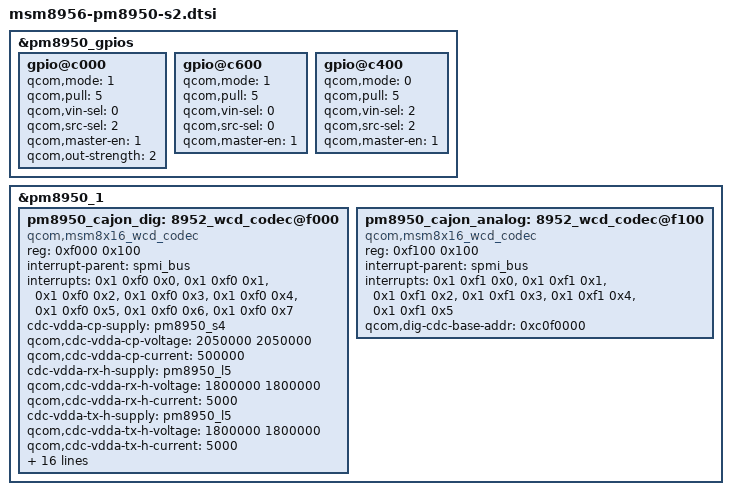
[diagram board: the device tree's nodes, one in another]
&pm8950_gpios {
	gpio@c000 {
		status = "ok";
		qcom,mode = <1>;
		qcom,pull = <5>;
		qcom,vin-sel = <0>;
		qcom,src-sel = <2>;
		qcom,master-en = <1>;
		qcom,out-strength = <2>;
	};
	gpio@c600 {
		status = "ok";
		qcom,mode = <1>;
		qcom,pull = <5>;
		qcom,vin-sel = <0>;
		qcom,src-sel = <0>;
		qcom,master-en = <1>;
	};
	gpio@c400 {
		qcom,mode = <0>;
		qcom,pull = <5>;
		qcom,vin-sel = <2>;
		qcom,src-sel = <2>;
		qcom,master-en = <1>;
		status = "okay";
	};
};


&pm8950_1 {
	pm8950_cajon_dig: 8952_wcd_codec@f000 {
		compatible = "qcom,msm8x16_wcd_codec";
		reg = <0xf000 0x100>;
		interrupt-parent = <&spmi_bus>;
		interrupts = <0x1 0xf0 0x0>,
			     <0x1 0xf0 0x1>,
			     <0x1 0xf0 0x2>,
			     <0x1 0xf0 0x3>,
			     <0x1 0xf0 0x4>,
			     <0x1 0xf0 0x5>,
			     <0x1 0xf0 0x6>,
			     <0x1 0xf0 0x7>;
		interrupt-names = "spk_cnp_int",
				  "spk_clip_int",
				  "spk_ocp_int",
				  "ins_rem_det1",
				  "but_rel_det",
				  "but_press_det",
				  "ins_rem_det",
				  "mbhc_int";

		cdc-vdda-cp-supply = <&pm8950_s4>;
		qcom,cdc-vdda-cp-voltage = <2050000 2050000>;
		qcom,cdc-vdda-cp-current = <500000>;
		
		cdc-vdda-rx-h-supply = <&pm8950_l5>;
		qcom,cdc-vdda-rx-h-voltage = <1800000 1800000>;
		qcom,cdc-vdda-rx-h-current = <5000>;

		cdc-vdda-tx-h-supply = <&pm8950_l5>;
		qcom,cdc-vdda-tx-h-voltage = <1800000 1800000>;
		qcom,cdc-vdda-tx-h-current = <5000>;

		cdc-vdd-px-supply = <&pm8950_l5>;
		qcom,cdc-vdd-px-voltage = <1800000 1800000>;
		qcom,cdc-vdd-px-current = <5000>;

		cdc-vdd-pa-supply = <&pm8950_s4>;
		qcom,cdc-vdd-pa-voltage = <2050000 2050000>;
		qcom,cdc-vdd-pa-current = <260000>;

		cdc-vdd-mic-bias-supply = <&pm8950_l13>;
		qcom,cdc-vdd-mic-bias-voltage = <3075000 3075000>;
		qcom,cdc-vdd-mic-bias-current = <5000>;
		qcom,cdc-micbias-cfilt-mv = <2800000 2800000>;
		qcom,cdc-mclk-clk-rate = <9600000>;

		qcom,cdc-static-supplies = "cdc-vdda-rx-h",
					   "cdc-vdda-tx-h",
					   "cdc-vdd-px",
					   "cdc-vdd-pa",
					   "cdc-vdda-cp";

		qcom,cdc-on-demand-supplies = "cdc-vdd-mic-bias";
		qcom,dig-cdc-base-addr = <0xc0f0000>;
	};

	pm8950_cajon_analog: 8952_wcd_codec@f100 {
		compatible = "qcom,msm8x16_wcd_codec";
		reg = <0xf100 0x100>;
		interrupt-parent = <&spmi_bus>;
		interrupts = <0x1 0xf1 0x0>,
			     <0x1 0xf1 0x1>,
			     <0x1 0xf1 0x2>,
			     <0x1 0xf1 0x3>,
			     <0x1 0xf1 0x4>,
			     <0x1 0xf1 0x5>;
		interrupt-names = "ear_ocp_int",
				  "hphr_ocp_int",
				  "hphl_ocp_det",
				  "ear_cnp_int",
				  "hphr_cnp_int",
				  "hphl_cnp_int";
		qcom,dig-cdc-base-addr = <0xc0f0000>;
	};
};
